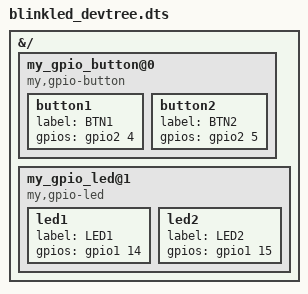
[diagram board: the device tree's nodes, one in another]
/dts-v1/;
/plugin/;

&{/} {
    my_gpio_button@0 {
        compatible = "my,gpio-button";
        status = "okay";

        button1 {
            label = "BTN1";
            gpios = <&gpio2 4 0>;   
        };

        button2 {
            label = "BTN2";
            gpios = <&gpio2 5 0>;   
        };
    };

    my_gpio_led@1 {
        compatible = "my,gpio-led";
        status = "okay";

        led1 {
            label = "LED1";
            gpios = <&gpio1 14 0>;  
        };

        led2 {
            label = "LED2";
            gpios = <&gpio1 15 0>;  
        };
    };
};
